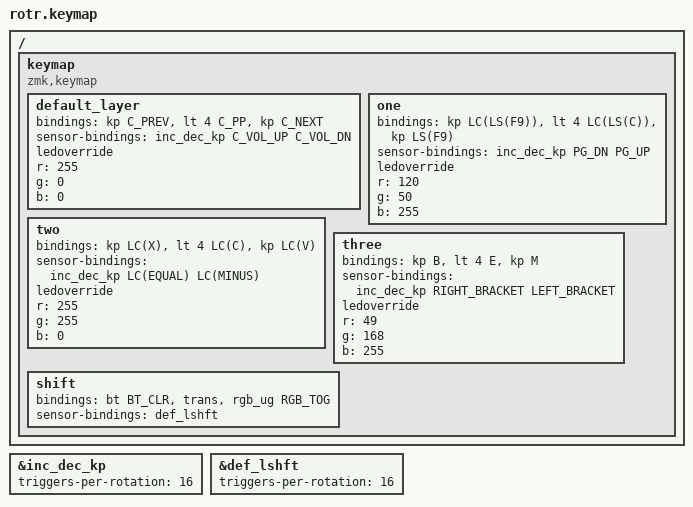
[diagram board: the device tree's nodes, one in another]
#include <behaviors.dtsi>
#include <dt-bindings/zmk/keys.h>
#include <dt-bindings/zmk/rgb.h>
#include <dt-bindings/zmk/bt.h>

&inc_dec_kp {
	triggers-per-rotation = <16>;
};
&def_lshft {
	triggers-per-rotation = <16>;
};

/ {
	keymap {
		compatible = "zmk,keymap";

		default_layer {
			//PREV | PLAY/PAUSE | NEXT
			bindings = <&kp C_PREV &lt 4 C_PP &kp C_NEXT>;
			sensor-bindings = <&inc_dec_kp C_VOL_UP C_VOL_DN>;
			ledoverride;
			r = <255>;
			g = <0>;
			b = <0>;
			// DEFAULT-MEDIA
		};
		one {
			//EASE OUT | PRE-COMPOSE | EASE IN
			bindings = <&kp LC(LS(F9)) &lt 4 LC(LS(C)) &kp LS(F9)>;
			sensor-bindings = <&inc_dec_kp PG_DN PG_UP>;
			ledoverride;
			r = <120>;
			g = <50>;
			b = <255>;
			// AFTER EFFECTS
		};
		two {
			//CUT | COPY | PASTE
			bindings = <&kp LC(X) &lt 4 LC(C) &kp LC(V)>;
			sensor-bindings = <&inc_dec_kp LC(EQUAL) LC(MINUS)>;
			ledoverride;
			r = <255>;
			g = <255>;
			b = <0>;
			// GENERAL
		};
		three {
			//BRUSH | ERASER | MARQUEE
			bindings = <&kp B &lt 4 E &kp M>;
			sensor-bindings = <&inc_dec_kp RIGHT_BRACKET LEFT_BRACKET>;
			ledoverride;
			r = <49>;
			g = <168>;
			b = <255>;
			// PHOTOSHOP
		};
		shift {
			//PREV | PLAY/PAUSE | NEXT
			bindings = <&bt BT_CLR &trans &rgb_ug RGB_TOG>;
			sensor-bindings = <&def_lshft>;
		};
	};
};
